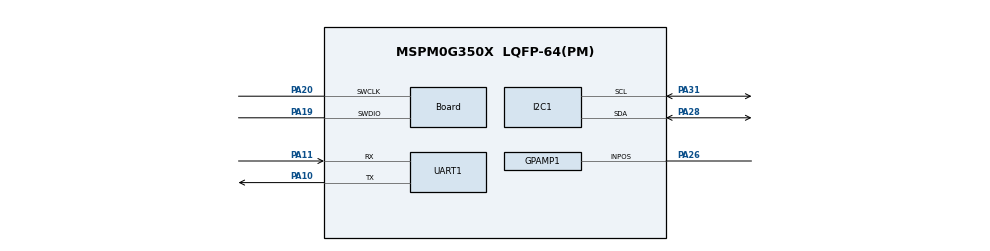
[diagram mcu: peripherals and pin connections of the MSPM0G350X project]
/**
 * @cliArgs --device "MSPM0G350X" --part "Default" --package "LQFP-64(PM)" --product "mspm0_sdk@1.30.00.03"
 * @versions {"tool":"1.21.1+3772"}
 */

/**
 * Import the modules used in this configuration.
 */
const GPAMP         = scripting.addModule("/ti/driverlib/GPAMP", {}, false);
const GPAMP1        = GPAMP.addInstance();
const I2C           = scripting.addModule("/ti/driverlib/I2C", {}, false);
const I2C1          = I2C.addInstance();
const OPA           = scripting.addModule("/ti/driverlib/OPA", {}, false);
const OPA1          = OPA.addInstance();
const OPA2          = OPA.addInstance();
const SYSCTL        = scripting.addModule("/ti/driverlib/SYSCTL");
const UART          = scripting.addModule("/ti/driverlib/UART", {}, false);
const UART1         = UART.addInstance();
const ProjectConfig = scripting.addModule("/ti/project_config/ProjectConfig");

/**
 * Write custom configuration values to the imported modules.
 */
GPAMP1.$name                       = "GPAMP_0";
GPAMP1.cfgPSELChannel              = "IN_POS";
GPAMP1.cfgNSELChannel              = "OUTPUT_PIN";
GPAMP1.peripheral.$assign          = "GPAMP";
GPAMP1.peripheral.InPosPin.$assign = "PA26";
GPAMP1.InPosPinConfig.$name        = "ti_driverlib_gpio_GPIOPinGeneric4";

const Board                       = scripting.addModule("/ti/driverlib/Board", {}, false);
Board.peripheral.$assign          = "DEBUGSS";
Board.peripheral.swclkPin.$assign = "PA20";
Board.peripheral.swdioPin.$assign = "PA19";

I2C1.$name                             = "I2C";
I2C1.basicEnableController             = true;
I2C1.advAnalogGlitchFilter             = "DISABLED";
I2C1.peripheral.$assign                = "I2C0";
I2C1.peripheral.sdaPin.$assign         = "PA28";
I2C1.peripheral.sclPin.$assign         = "PA31";
I2C1.sdaPinConfig.hideOutputInversion  = scripting.forceWrite(false);
I2C1.sdaPinConfig.onlyInternalResistor = scripting.forceWrite(false);
I2C1.sdaPinConfig.passedPeripheralType = scripting.forceWrite("Digital");
I2C1.sdaPinConfig.$name                = "ti_driverlib_gpio_GPIOPinGeneric2";
I2C1.sclPinConfig.hideOutputInversion  = scripting.forceWrite(false);
I2C1.sclPinConfig.onlyInternalResistor = scripting.forceWrite(false);
I2C1.sclPinConfig.passedPeripheralType = scripting.forceWrite("Digital");
I2C1.sclPinConfig.$name                = "ti_driverlib_gpio_GPIOPinGeneric3";

OPA1.$name              = "OPA_1";
OPA1.peripheral.$assign = "OPA1";

OPA2.$name              = "OPA_0";
OPA2.peripheral.$assign = "OPA0";

SYSCTL.forceDefaultClkConfig = true;
SYSCTL.clockTreeEn           = true;

UART1.$name                    = "UART_0";
UART1.targetBaudRate           = 115200;
UART1.uartClkDiv               = "4";
UART1.enabledInterrupts        = ["RX"];
UART1.peripheral.$assign       = "UART0";
UART1.peripheral.rxPin.$assign = "PA11";
UART1.peripheral.txPin.$assign = "PA10";
UART1.txPinConfig.$name        = "ti_driverlib_gpio_GPIOPinGeneric0";
UART1.rxPinConfig.$name        = "ti_driverlib_gpio_GPIOPinGeneric1";

ProjectConfig.switchCondition = true;
